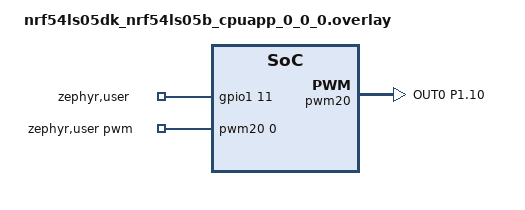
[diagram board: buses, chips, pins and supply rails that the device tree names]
/*
 * Copyright (c) 2025 Nordic Semiconductor ASA
 *
 * SPDX-License-Identifier: LicenseRef-Nordic-5-Clause
 */

/ {
	zephyr,user {
		pwms = <&pwm20 0 160000 PWM_POLARITY_NORMAL>;
		gpios = <&gpio1 11 GPIO_ACTIVE_HIGH>;
	};
};

&pinctrl {
	pwm20_alt: pwm20_alt {
		group1 {
			psels = <NRF_PSEL(PWM_OUT0, 1, 10)>;
		};
	};

	pwm20_alt_sleep: pwm20_alt_sleep {
		group1 {
			psels = <NRF_PSEL(PWM_OUT0, 1, 10)>;
			low-power-enable;
		};
	};
};

&pwm20 {
	pinctrl-0 = <&pwm20_alt>;
	pinctrl-1 = <&pwm20_alt_sleep>;
	pinctrl-names = "default", "sleep";
	status = "okay";
};
